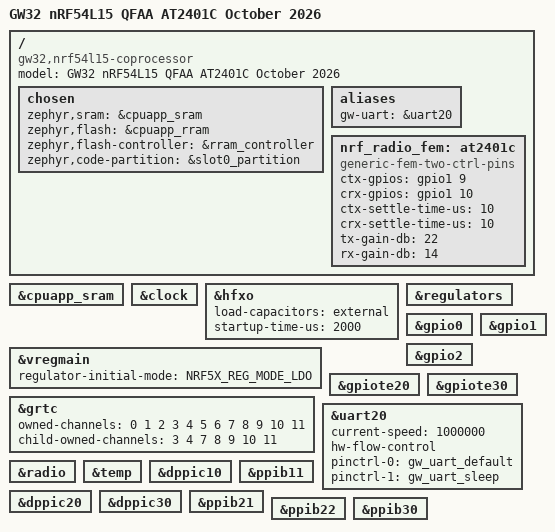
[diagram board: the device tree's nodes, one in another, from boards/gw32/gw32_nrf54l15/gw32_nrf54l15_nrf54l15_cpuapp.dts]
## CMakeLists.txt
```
cmake_minimum_required(VERSION 3.20.0)
list(APPEND BOARD_ROOT ${CMAKE_CURRENT_SOURCE_DIR})
find_package(Zephyr REQUIRED HINTS $ENV{ZEPHYR_BASE})
project(gw32_nrf54l15 VERSION 0.3.0 LANGUAGES C)

target_sources(app PRIVATE
  src/main.c src/gw_app.c src/gw_core.c src/gw_filter_v2.c src/gw_radio.c src/gw_gatt.c
  src/gw_peripheral.c src/gw_dfu.c)
target_include_directories(app PRIVATE src)
target_compile_options(app PRIVATE -Wall -Wextra)
```

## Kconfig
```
mainmenu "GW32 nRF54L15 BLE coprocessor"

config GW_RADIO_VERIFIED
	bool "Enable BLE operation on the selected hardware"
	default y if BOARD_NRF54L15DK
	default n
	help
	  The official DK is usable for software development immediately. For
	  GW32 custom hardware, enable only after validating the schematic
	  revision, oscillator startup and FEM timing and RF output power.
	  With this disabled the UART management protocol remains available
	  and BLE commands report unsupported; no radio capability is advertised.

config GW_DFU
	bool "ESP UART firmware upgrade with signed MCUboot images"
	default n
	depends on BOOTLOADER_MCUBOOT && MCUBOOT_BOOTLOADER_MODE_SWAP_USING_OFFSET
	depends on IMG_MANAGER && IMG_ENABLE_IMAGE_CHECK
	help
	  Receive firmware only into the secondary slot. A trusted, board-specific
	  signing key and a MCUboot sysbuild are required. A normal application
	  build does not advertise UART DFU capability.

config GW_DFU_CONFIRM_TIMEOUT_MS
	int "Trial firmware confirmation timeout (ms)"
	default 120000
	range 30000 600000
	depends on GW_DFU
	help
	  Reset an unconfirmed trial image if ESP does not explicitly confirm it
	  after checking its version and health. MCUboot reverts on the next boot.

source "Kconfig.zephyr"
```

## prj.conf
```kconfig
# UART20 belongs exclusively to the binary gateway protocol.
CONFIG_SERIAL=y
CONFIG_UART_ASYNC_API=y
CONFIG_UART_20_ASYNC=y
CONFIG_UART_USE_RUNTIME_CONFIGURE=y
CONFIG_CONSOLE=n
CONFIG_UART_CONSOLE=n
CONFIG_PRINTK=n

CONFIG_GPIO=y
CONFIG_CLOCK_CONTROL=y
CONFIG_BT=y
CONFIG_BT_CENTRAL=y
CONFIG_BT_OBSERVER=y
CONFIG_BT_BROADCASTER=y
CONFIG_BT_PERIPHERAL=y
CONFIG_BT_GATT_CLIENT=y
CONFIG_BT_MAX_CONN=1
CONFIG_BT_MAX_PAIRED=4
CONFIG_BT_SMP=y
CONFIG_BT_SMP_APP_PAIRING_ACCEPT=y
CONFIG_BT_SETTINGS=y
CONFIG_BT_EXT_ADV=n
CONFIG_BT_DEVICE_NAME="GW32-nRF54L15"
CONFIG_BT_L2CAP_TX_MTU=247
CONFIG_BT_BUF_ACL_RX_SIZE=251
CONFIG_BT_BUF_ACL_TX_SIZE=251

CONFIG_FLASH=y
CONFIG_FLASH_MAP=y
CONFIG_NVS=y
CONFIG_SETTINGS=y
CONFIG_SETTINGS_NVS=y
CONFIG_REBOOT=y
CONFIG_ENTROPY_GENERATOR=y
CONFIG_HARDWARE_DEVICE_CS_GENERATOR=y

# RTT cannot corrupt binary UART frames.
CONFIG_LOG=y
CONFIG_LOG_MODE_DEFERRED=y
CONFIG_LOG_BACKEND_UART=n
CONFIG_USE_SEGGER_RTT=y
CONFIG_LOG_BACKEND_RTT=y
CONFIG_LOG_DEFAULT_LEVEL=3
CONFIG_MAIN_STACK_SIZE=12288
CONFIG_SYSTEM_WORKQUEUE_STACK_SIZE=4096
CONFIG_HEAP_MEM_POOL_SIZE=8192
CONFIG_ASSERT=y
CONFIG_STACK_SENTINEL=y
```

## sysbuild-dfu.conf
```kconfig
SB_CONFIG_BOOTLOADER_MCUBOOT=y
SB_CONFIG_MCUBOOT_MODE_SWAP_USING_OFFSET=y
SB_CONFIG_BOOT_SIGNATURE_TYPE_ECDSA_P256=y
# The build invocation must supply SB_CONFIG_BOOT_SIGNATURE_KEY_FILE.
# Never release an image signed with MCUboot's public example private key.
```

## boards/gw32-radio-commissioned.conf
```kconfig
# Apply only after the commissioning steps in README.md have passed.
CONFIG_GW_RADIO_VERIFIED=y
```

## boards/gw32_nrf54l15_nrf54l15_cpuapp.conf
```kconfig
CONFIG_MPSL_FEM=y
CONFIG_MPSL_FEM_SIMPLE_GPIO=y
CONFIG_GW_RADIO_VERIFIED=n
```

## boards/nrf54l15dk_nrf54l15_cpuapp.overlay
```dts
/* Development kit only. These are protocol pins, not a text console. */
#include <zephyr/dt-bindings/pinctrl/nrf-pinctrl.h>

/ {
	aliases { gw-uart = &uart20; };
};

&pinctrl {
	gw_uart_default: gw_uart_default {
		group1 {
			psels = <NRF_PSEL(UART_TX, 1, 4)>, <NRF_PSEL(UART_RTS, 1, 6)>;
		};
		group2 {
			psels = <NRF_PSEL(UART_RX, 1, 5)>, <NRF_PSEL(UART_CTS, 1, 7)>;
			bias-pull-up;
		};
	};
	gw_uart_sleep: gw_uart_sleep {
		group1 {
			psels = <NRF_PSEL(UART_TX, 1, 4)>, <NRF_PSEL(UART_RX, 1, 5)>,
				<NRF_PSEL(UART_RTS, 1, 6)>, <NRF_PSEL(UART_CTS, 1, 7)>;
			low-power-enable;
		};
	};
};

&uart20 {
	status = "okay";
	current-speed = <1000000>;
	hw-flow-control;
	pinctrl-0 = <&gw_uart_default>;
	pinctrl-1 = <&gw_uart_sleep>;
	pinctrl-names = "default", "sleep";
};
```

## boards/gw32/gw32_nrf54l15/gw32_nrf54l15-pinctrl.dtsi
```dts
#include <zephyr/dt-bindings/pinctrl/nrf-pinctrl.h>

&pinctrl {
	gw_uart_default: gw_uart_default {
		group1 {
			psels = <NRF_PSEL(UART_TX, 1, 4)>, <NRF_PSEL(UART_RTS, 1, 6)>;
		};
		group2 {
			psels = <NRF_PSEL(UART_RX, 1, 5)>, <NRF_PSEL(UART_CTS, 1, 7)>;
			bias-pull-up;
		};
	};
	gw_uart_sleep: gw_uart_sleep {
		group1 {
			psels = <NRF_PSEL(UART_TX, 1, 4)>, <NRF_PSEL(UART_RX, 1, 5)>,
				<NRF_PSEL(UART_RTS, 1, 6)>, <NRF_PSEL(UART_CTS, 1, 7)>;
			low-power-enable;
		};
	};
};
```

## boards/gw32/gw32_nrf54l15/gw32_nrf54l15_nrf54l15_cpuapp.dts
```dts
/dts-v1/;

#include <nordic/nrf54l15_cpuapp.dtsi>
#include <zephyr/dt-bindings/gpio/gpio.h>
#include <zephyr/dt-bindings/regulator/nrf5x.h>
#include "gw32_nrf54l15-pinctrl.dtsi"

/ {
	model = "GW32 nRF54L15 QFAA AT2401C October 2026";
	compatible = "gw32,nrf54l15-coprocessor";
	chosen {
		zephyr,sram = &cpuapp_sram;
		zephyr,flash = &cpuapp_rram;
		zephyr,flash-controller = &rram_controller;
		zephyr,code-partition = &slot0_partition;
	};
	aliases { gw-uart = &uart20; };

	/* NCS v3.2.1 compatible; MPSL owns these pins and their timing. */
	nrf_radio_fem: at2401c {
		compatible = "generic-fem-two-ctrl-pins";
		ctx-gpios = <&gpio1 9 GPIO_ACTIVE_HIGH>;
		crx-gpios = <&gpio1 10 GPIO_ACTIVE_HIGH>;
		/* Datasheet 0.8 us is typical. 10 us is a bench starting value. */
		ctx-settle-time-us = <10>;
		crx-settle-time-us = <10>;
		tx-gain-db = <22>;
		rx-gain-db = <14>;
	};
};

#include <nordic/nrf54l15_partition.dtsi>

&cpuapp_sram { status = "okay"; };
&clock { status = "okay"; };
&hfxo {
	load-capacitors = "external";
	/* Conservative initial allowance, requires XOSTART/XOTUNED measurement. */
	startup-time-us = <2000>;
};
&regulators { status = "okay"; };
&vregmain {
	status = "okay";
	regulator-initial-mode = <NRF5X_REG_MODE_LDO>;
};
&gpio0 { status = "okay"; };
&gpio1 { status = "okay"; };
&gpio2 { status = "okay"; };
&gpiote20 { status = "okay"; };
&gpiote30 { status = "okay"; };
&grtc {
	owned-channels = <0 1 2 3 4 5 6 7 8 9 10 11>;
	child-owned-channels = <3 4 7 8 9 10 11>;
	status = "okay";
};
&uart20 {
	status = "okay";
	current-speed = <1000000>;
	hw-flow-control;
	pinctrl-0 = <&gw_uart_default>;
	pinctrl-1 = <&gw_uart_sleep>;
	pinctrl-names = "default", "sleep";
};
&radio { status = "okay"; };
&temp { status = "okay"; };
&dppic10 { status = "okay"; };
&dppic20 { status = "okay"; };
&dppic30 { status = "okay"; };
&ppib11 { status = "okay"; };
&ppib21 { status = "okay"; };
&ppib22 { status = "okay"; };
&ppib30 { status = "okay"; };
```

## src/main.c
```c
#include <zephyr/kernel.h>
#include <zephyr/logging/log.h>

LOG_MODULE_REGISTER(gw_main, LOG_LEVEL_INF);
int gw_app_run(void);

int main(void)
{
    int err = gw_app_run();
    LOG_ERR("Gateway stopped: %d", err);
    return err;
}
```

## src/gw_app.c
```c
#include "gw_core.h"
#include "gw_gatt.h"
#include "gw_peripheral.h"
#include "gw_dfu.h"
#include "gw_radio.h"
#include <errno.h>
#include <string.h>
#include <zephyr/kernel.h>
#include <zephyr/device.h>
#include <zephyr/drivers/uart.h>
#include <zephyr/drivers/clock_control/nrf_clock_control.h>
#include <zephyr/random/random.h>
#include <zephyr/sys/atomic.h>
#include <zephyr/sys/reboot.h>
#include <zephyr/sys/ring_buffer.h>
#include <zephyr/logging/log.h>

LOG_MODULE_REGISTER(gw_app, LOG_LEVEL_INF);

#define RX_DMA_SIZE 256
#define RX_DMA_COUNT 3
#define RX_RING_SIZE 8192
#define FW_VERSION "gw-nrf54l15/0.3.0"

static const struct device *const link_uart = DEVICE_DT_GET(DT_ALIAS(gw_uart));
static uint8_t rx_dma[RX_DMA_COUNT][RX_DMA_SIZE] __aligned(4);
static atomic_t rx_owned[RX_DMA_COUNT];
static atomic_t rx_disabled = ATOMIC_INIT(1);
static atomic_t rx_overflow;
static atomic_t rx_driver_errors;
static atomic_t tx_busy;
static atomic_t tx_success;
static uint8_t tx_wire[GW_WIRE_MAX] __aligned(4);
RING_BUF_DECLARE(rx_ring, RX_RING_SIZE);
K_SEM_DEFINE(tx_done, 0, 1);
K_MUTEX_DEFINE(queue_lock);

static struct gw_queue queue;
static struct gw_decoder decoder;
static struct gw_frame incoming;
static struct gw_frame outgoing;
static struct gw_frame cached_response;
static uint8_t cached_request[GW_PAYLOAD_MAX];
static uint16_t cached_request_length;
static uint32_t last_command;
static uint8_t boot_id[16];
static uint64_t link_id;
static bool link_established;
static uint64_t dropped_full, bad_rx, retries;
static uint64_t next_batch_send_ms;
static uint64_t ack_deadline_ms;
static uint32_t sent_batch;
static uint32_t retry_backoff_ms = 250;

static int hold_uart_hfxo(void)
{
    /* NCS v3.2.1 UARTE does not own the crystal request. Use the clock
     * manager shared with MPSL; never directly trigger clock hardware. */
    static struct onoff_client client;
    struct onoff_manager *manager =
        z_nrf_clock_control_get_onoff(CLOCK_CONTROL_NRF_SUBSYS_HF);
    if (!manager) {
        return -ENODEV;
    }
    sys_notify_init_spinwait(&client.notify);
    int err = onoff_request(manager, &client);
    if (err < 0) {
        return err;
    }
    int result = 0;
    int64_t deadline = k_uptime_get() + 2000;
    while ((err = sys_notify_fetch_result(&client.notify, &result)) == -EAGAIN &&
           k_uptime_get() < deadline) {
        k_sleep(K_MSEC(1));
    }
    if (err < 0 || result < 0) {
        (void)onoff_cancel_or_release(manager, &client);
        return err < 0 ? err : result;
    }
    /* Continuous RX owns this reference until reboot. */
    return 0;
}

static int claim_rx_buffer(void)
{
    for (int i = 0; i < RX_DMA_COUNT; ++i) {
        if (atomic_cas(&rx_owned[i], 0, 1)) {
            return i;
        }
    }
    return -1;
}

static void uart_event(const struct device *dev, struct uart_event *event, void *unused)
{
    ARG_UNUSED(unused);
    switch (event->type) {
    case UART_RX_RDY: {
        const uint8_t *data = event->data.rx.buf + event->data.rx.offset;
        size_t length = event->data.rx.len;
        if (ring_buf_put(&rx_ring, data, length) != length) {
            atomic_inc(&rx_overflow);
        }
        break;
    }
    case UART_RX_BUF_REQUEST: {
        int slot = claim_rx_buffer();
        if (slot >= 0 && uart_rx_buf_rsp(dev, rx_dma[slot], RX_DMA_SIZE) != 0) {
            atomic_clear(&rx_owned[slot]);
        }
        break;
    }
    case UART_RX_BUF_RELEASED:
        for (int i = 0; i < RX_DMA_COUNT; ++i) {
            if (event->data.rx_buf.buf == rx_dma[i]) {
                atomic_clear(&rx_owned[i]);
                break;
            }
        }
        break;
    case UART_RX_DISABLED:
        atomic_set(&rx_disabled, 1);
        break;
    case UART_RX_STOPPED:
        atomic_inc(&rx_driver_errors);
        break;
    case UART_TX_DONE:
        atomic_set(&tx_success, 1);
        atomic_clear(&tx_busy);
        k_sem_give(&tx_done);
        break;
    case UART_TX_ABORTED:
        atomic_clear(&tx_success);
        atomic_clear(&tx_busy);
        k_sem_give(&tx_done);
        break;
    default:
        break;
    }
}

static void restart_rx(void)
{
    if (!atomic_cas(&rx_disabled, 1, 0)) {
        return;
    }
    int slot = claim_rx_buffer();
    if (slot < 0) {
        atomic_set(&rx_disabled, 1);
        return;
    }
    /* A short idle timeout delivers a partial command without awaiting 256 bytes. */
    int err = uart_rx_enable(link_uart, rx_dma[slot], RX_DMA_SIZE, 1000);
    if (err) {
        atomic_clear(&rx_owned[slot]);
        atomic_set(&rx_disabled, 1);
    }
}

static int send_frame(const struct gw_frame *frame)
{
    if (atomic_get(&tx_busy)) {
        return -EBUSY;
    }
    size_t length = gw_encode_frame(frame, tx_wire, sizeof(tx_wire));
    if (!length) {
        return -EINVAL;
    }
    k_sem_reset(&tx_done);
    atomic_clear(&tx_success);
    atomic_set(&tx_busy, 1);
    /* The DMA buffer is never reused until DONE or ABORTED releases ownership. */
    int err = uart_tx(link_uart, tx_wire, length, 200000);
    if (err) {
        atomic_clear(&tx_busy);
        return err;
    }
    if (k_sem_take(&tx_done, K_MSEC(300))) {
        (void)uart_tx_abort(link_uart);
        (void)k_sem_take(&tx_done, K_MSEC(100));
        return -ETIMEDOUT;
    }
    return atomic_get(&tx_success) ? 0 : -ETIMEDOUT;
}

bool gw_app_record(uint8_t type, const uint8_t *record, size_t length)
{
    k_mutex_lock(&queue_lock, K_FOREVER);
    bool accepted = gw_queue_push(&queue, type, record, length, k_uptime_get());
    if (!accepted) {
        dropped_full++;
    }
    k_mutex_unlock(&queue_lock);
    return accepted;
}

static void gatt_record(const uint8_t *record, size_t length)
{
    (void)gw_app_record(0x21, record, length);
}

static size_t encode_status(uint8_t *out)
{
    uint64_t seen, filtered, incomplete;
    gw_radio_counters(&seen, &filtered, &incomplete);
    gw_put_u64(out, k_uptime_get());
    gw_put_u64(out + 8, gw_radio_revision());
    out[16] = gw_radio_scan_state();
    k_mutex_lock(&queue_lock, K_FOREVER);
    gw_put_u16(out + 17, queue.count);
    gw_put_u32(out + 19, queue.used_bytes);
    gw_put_u64(out + 39, dropped_full);
    k_mutex_unlock(&queue_lock);
    gw_put_u64(out + 23, seen);
    gw_put_u64(out + 31, filtered);
    gw_put_u64(out + 47, incomplete);
    gw_put_u64(out + 55, bad_rx);
    gw_put_u64(out + 63, retries);
    return 71;
}

static uint8_t dispatch_command(uint8_t opcode, const uint8_t *args, size_t length,
                                uint8_t *out, size_t *out_length, uint64_t received_ms)
{
    *out_length = 0;
    if (opcode >= 0x30 && opcode <= 0x37) {
        return gw_dfu_command(opcode, args, length, out, out_length);
    }
    if (gw_dfu_active() && opcode != 0x02 && opcode != 0x03 && opcode != 0x04 &&
        opcode != 0x06 && opcode != 0x08 && opcode != 0x09 && opcode != 0x0a &&
        opcode != 0x0c && opcode != 0x0d && opcode != 0x17 &&
        opcode != 0x1a && opcode != 0x1b) {
        return GW_BUSY;
    }
    switch (opcode) {
    case 0x03:
        if (length) {
            return GW_BAD_PARAM;
        }
        *out_length = encode_status(out);
        return GW_OK;
    case 0x04:
        if (length) {
            return GW_BAD_PARAM;
        }
        gw_put_u64(out, received_ms);
        gw_put_u64(out + 8, k_uptime_get());
        *out_length = 16;
        return GW_OK;
    case 0x0a:
    case 0x10: case 0x11: case 0x12: case 0x13: case 0x14:
    case 0x15: case 0x16: case 0x17: case 0x18:
        if (!(gw_radio_capabilities() & BIT(2))) {
            return GW_UNSUPPORTED;
        }
        return gw_gatt_command(opcode, args, length, out, out_length);
    case 0x0d: case 0x0e: case 0x0f:
        if (!(gw_radio_capabilities() & BIT(11))) {
            return GW_UNSUPPORTED;
        }
        return gw_peripheral_command(opcode, args, length, out, out_length);
    default:
        return gw_radio_command(opcode, args, length, out, out_length);
    }
}

static void handle_hello(const struct gw_frame *request)
{
    if (request->payload_len || request->msg_id || !request->link_id) {
        bad_rx++;
        return;
    }
    if (request->link_id != link_id) {
        link_id = request->link_id;
        last_command = 0;
        cached_request_length = 0;
        /* FIFO, frozen batch, config, conn_id and GATT op cache survive relinking. */
    }
    link_established = false;
    outgoing.type = 0x81;
    outgoing.link_id = link_id;
    outgoing.msg_id = 0;
    memcpy(outgoing.payload, boot_id, sizeof(boot_id));
    gw_put_u32(outgoing.payload + 16, gw_radio_capabilities() |
               (gw_dfu_available() ? BIT(12) : 0));
    outgoing.payload[20] = sizeof(FW_VERSION) - 1;
    memcpy(outgoing.payload + 21, FW_VERSION, sizeof(FW_VERSION) - 1);
    outgoing.payload_len = 21 + sizeof(FW_VERSION) - 1;
    if (send_frame(&outgoing) == 0) {
        link_established = true;
        ack_deadline_ms = 0;
        next_batch_send_ms = k_uptime_get();
    }
}

static void handle_command(const struct gw_frame *request, uint64_t received_ms)
{
    if (!request->msg_id || !request->payload_len) {
        bad_rx++;
        return;
    }
    if (request->msg_id < last_command) {
        return;
    }
    if (request->msg_id == last_command) {
        if (request->payload_len == cached_request_length &&
            !memcmp(request->payload, cached_request, cached_request_length)) {
            (void)send_frame(&cached_response);
        } else {
            outgoing.type = 0x90;
            outgoing.link_id = link_id;
            outgoing.msg_id = request->msg_id;
            outgoing.payload_len = 2;
            outgoing.payload[0] = request->payload[0];
            outgoing.payload[1] = GW_CONFLICT;
            (void)send_frame(&outgoing);
        }
        return;
    }
    uint8_t opcode = request->payload[0];
    cached_response.type = 0x90;
    cached_response.link_id = link_id;
    cached_response.msg_id = request->msg_id;
    cached_response.payload[0] = opcode;
    size_t result_length = 0;
    uint8_t status = dispatch_command(opcode, request->payload + 1,
                                     request->payload_len - 1,
                                     cached_response.payload + 2, &result_length,
                                     received_ms);
    cached_response.payload[1] = status;
    cached_response.payload_len = 2 + (status == GW_OK ? result_length : 0);
    last_command = request->msg_id;
    cached_request_length = request->payload_len;
    memcpy(cached_request, request->payload, cached_request_length);
    /* Cache even when TX fails: a host retry must not repeat a physical action. */
    (void)send_frame(&cached_response);
}

static void handle_ack(const struct gw_frame *request)
{
    if (request->payload_len != 3) {
        bad_rx++;
        return;
    }
    uint8_t status = request->payload[0];
    uint16_t interval = gw_get_u16(request->payload + 1);
    if (status > 2 || (status == 1 ? (interval < 250 || interval > 5000) : interval != 0)) {
        bad_rx++;
        return;
    }
    k_mutex_lock(&queue_lock, K_FOREVER);
    bool matched = gw_queue_ack(&queue, request->msg_id, status);
    k_mutex_unlock(&queue_lock);
    if (!matched) {
        return;
    }
    ack_deadline_ms = 0;
    next_batch_send_ms = k_uptime_get() + interval;
    if (status == 0) {
        sent_batch = 0;
        retry_backoff_ms = 250;
    }
}

static void receive_frames(void)
{
    uint8_t bytes[128];
    uint32_t count;
    uint32_t overflow = atomic_set(&rx_overflow, 0);
    uint32_t driver_errors = atomic_set(&rx_driver_errors, 0);
    if (overflow || driver_errors) {
        bad_rx += overflow + driver_errors;
        decoder.length = 0;
        decoder.discard = true;
    }
    /* Bound each turn so notifications, deadlines and driver recovery progress. */
    for (size_t budget = 0; budget < RX_RING_SIZE; budget += count) {
        count = ring_buf_get(&rx_ring, bytes, sizeof(bytes));
        if (!count) {
            break;
        }
        for (size_t i = 0; i < count; ++i) {
            int decoded = gw_decoder_feed(&decoder, bytes[i], &incoming);
            if (decoded < 0) {
                bad_rx++;
            } else if (decoded > 0) {
                uint64_t received_ms = k_uptime_get();
                if (incoming.type == 0x01) {
                    handle_hello(&incoming);
                } else if (link_established && incoming.link_id == link_id) {
                    if (incoming.type == 0x10) {
                        handle_command(&incoming, received_ms);
                    } else if (incoming.type == 0xa0) {
                        handle_ack(&incoming);
                    } else {
                        bad_rx++;
                    }
                }
            }
        }
    }
}

static void transmit_batch(void)
{
    uint64_t now = k_uptime_get();
    if (!link_established || atomic_get(&tx_busy)) {
        return;
    }
    if (ack_deadline_ms) {
        if (now < ack_deadline_ms) {
            return;
        }
        ack_deadline_ms = 0;
        next_batch_send_ms = now + retry_backoff_ms + sys_rand32_get() % 101;
        retry_backoff_ms = MIN(retry_backoff_ms * 2, 5000);
    }
    if (now < next_batch_send_ms) {
        return;
    }
    k_mutex_lock(&queue_lock, K_FOREVER);
    bool ready = gw_queue_batch(&queue, now, &outgoing);
    bool exhausted = !queue.count && (queue.next_sequence == UINT64_MAX || !queue.next_batch);
    k_mutex_unlock(&queue_lock);
    if (exhausted) {
        sys_reboot(SYS_REBOOT_COLD);
        return;
    }
    if (!ready) {
        return;
    }
    outgoing.link_id = link_id;
    if (sent_batch == outgoing.msg_id) {
        retries++;
    }
    sent_batch = outgoing.msg_id;
    if (send_frame(&outgoing) == 0) {
        ack_deadline_ms = k_uptime_get() + 500;
    } else {
        next_batch_send_ms = k_uptime_get() + retry_backoff_ms + sys_rand32_get() % 101;
        retry_backoff_ms = MIN(retry_backoff_ms * 2, 5000);
    }
}

int gw_app_run(void)
{
    gw_queue_init(&queue);
    gw_decoder_init(&decoder);
    int err = gw_dfu_init();
    if (err) {
        LOG_ERR("DFU unavailable (%d); UART diagnostics remain enabled", err);
    }
    /* Never reuse a constant boot identifier if the entropy device fails. */
    err = hold_uart_hfxo();
    if (err) {
        return err;
    }
    err = sys_csrand_get(boot_id, sizeof(boot_id));
    if (err) {
        return err;
    }
    err = gw_radio_init();
    if (err) {
        LOG_ERR("Bluetooth unavailable (%d); UART diagnostics remain enabled", err);
    }
    err = gw_gatt_init(gatt_record);
    if (err) {
        return err;
    }
    err = gw_peripheral_init();
    if (err) {
        return err;
    }
    if (!device_is_ready(link_uart)) {
        return -ENODEV;
    }
    const struct uart_config config = {
        .baudrate = 1000000,
        .parity = UART_CFG_PARITY_NONE,
        .stop_bits = UART_CFG_STOP_BITS_1,
        .data_bits = UART_CFG_DATA_BITS_8,
        .flow_ctrl = UART_CFG_FLOW_CTRL_RTS_CTS,
    };
    err = uart_configure(link_uart, &config);
    if (err) {
        return err;
    }
    err = uart_callback_set(link_uart, uart_event, NULL);
    if (err) {
        return err;
    }
    LOG_INF("Gateway %s started (capabilities 0x%x)", FW_VERSION, gw_radio_capabilities());
    restart_rx();
    for (;;) {
        restart_rx();
        receive_frames();
        gw_gatt_poll();
        gw_peripheral_poll();
        gw_dfu_poll();
        gw_radio_poll();
        transmit_batch();
        k_sleep(K_MSEC(1));
    }
}
```

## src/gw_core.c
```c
#include "gw_core.h"

#include <limits.h>
#include <string.h>

uint16_t gw_get_u16(const uint8_t *p)
{
    return (uint16_t)p[0] | (uint16_t)((uint16_t)p[1] << 8);
}

uint32_t gw_get_u32(const uint8_t *p)
{
    return (uint32_t)p[0] | ((uint32_t)p[1] << 8) |
           ((uint32_t)p[2] << 16) | ((uint32_t)p[3] << 24);
}

uint64_t gw_get_u64(const uint8_t *p)
{
    return (uint64_t)gw_get_u32(p) | ((uint64_t)gw_get_u32(p + 4) << 32);
}

void gw_put_u16(uint8_t *p, uint16_t value)
{
    p[0] = (uint8_t)value;
    p[1] = (uint8_t)(value >> 8);
}

void gw_put_u32(uint8_t *p, uint32_t value)
{
    for (unsigned int i = 0; i < 4; ++i) {
        p[i] = (uint8_t)(value >> (i * 8));
    }
}

void gw_put_u64(uint8_t *p, uint64_t value)
{
    gw_put_u32(p, (uint32_t)value);
    gw_put_u32(p + 4, (uint32_t)(value >> 32));
}

uint32_t gw_crc32c(const uint8_t *data, size_t length)
{
    uint32_t crc = UINT32_MAX;

    for (size_t i = 0; i < length; ++i) {
        crc ^= data[i];
        for (unsigned int bit = 0; bit < 8; ++bit) {
            uint32_t mask = 0U - (crc & 1U);
            crc = (crc >> 1) ^ (UINT32_C(0x82f63b78) & mask);
        }
    }
    return crc ^ UINT32_MAX;
}

size_t gw_encode_frame(const struct gw_frame *frame, uint8_t *wire, size_t capacity)
{
    uint8_t raw[GW_RAW_MAX];
    size_t raw_length;
    size_t written = 2;
    size_t code_offset = 1;
    uint8_t code = 1;

    if (frame == NULL || wire == NULL || frame->payload_len > GW_PAYLOAD_MAX) {
        return 0;
    }
    raw_length = 22U + frame->payload_len;
    if (capacity < raw_length + raw_length / 254U + 3U) {
        return 0;
    }
    raw[0] = 0x47;
    raw[1] = 0x57;
    raw[2] = 1;
    raw[3] = frame->type;
    gw_put_u16(raw + 4, frame->payload_len);
    gw_put_u64(raw + 6, frame->link_id);
    gw_put_u32(raw + 14, frame->msg_id);
    memcpy(raw + 18, frame->payload, frame->payload_len);
    gw_put_u32(raw + raw_length - 4, gw_crc32c(raw, raw_length - 4));
    wire[0] = 0;
    for (size_t i = 0; i < raw_length; ++i) {
        if (raw[i] == 0) {
            wire[code_offset] = code;
            code_offset = written++;
            code = 1;
        } else {
            wire[written++] = raw[i];
            ++code;
            if (code == 255) {
                wire[code_offset] = code;
                code_offset = written++;
                code = 1;
            }
        }
    }
    wire[code_offset] = code;
    wire[written++] = 0;
    return written;
}

bool gw_decode_frame(const uint8_t *encoded, size_t length, struct gw_frame *frame)
{
    uint8_t raw[GW_RAW_MAX];
    size_t pos = 0;
    size_t decoded = 0;

    if (encoded == NULL || frame == NULL || length == 0 || length > GW_ENCODED_MAX) {
        return false;
    }
    while (pos < length) {
        uint8_t code = encoded[pos++];
        size_t run = (size_t)code - 1U;

        if (code == 0 || run > length - pos || run > sizeof(raw) - decoded) {
            return false;
        }
        for (size_t i = 0; i < run; ++i) {
            if (encoded[pos + i] == 0) {
                return false;
            }
        }
        memcpy(raw + decoded, encoded + pos, run);
        decoded += run;
        pos += run;
        if (code < 255 && pos < length) {
            if (decoded == sizeof(raw)) {
                return false;
            }
            raw[decoded++] = 0;
        }
    }
    if (decoded < 22 || raw[0] != 0x47 || raw[1] != 0x57 || raw[2] != 1 ||
        gw_get_u16(raw + 4) != decoded - 22 ||
        gw_get_u32(raw + decoded - 4) != gw_crc32c(raw, decoded - 4)) {
        return false;
    }
    frame->type = raw[3];
    frame->payload_len = gw_get_u16(raw + 4);
    frame->link_id = gw_get_u64(raw + 6);
    frame->msg_id = gw_get_u32(raw + 14);
    memcpy(frame->payload, raw + 18, frame->payload_len);
    return true;
}

void gw_decoder_init(struct gw_decoder *decoder)
{
    memset(decoder, 0, sizeof(*decoder));
}

int gw_decoder_feed(struct gw_decoder *decoder, uint8_t byte, struct gw_frame *frame)
{
    if (byte == 0) {
        int result = 0;

        if (decoder->discard) {
            result = -1;
        } else if (decoder->length != 0) {
            result = gw_decode_frame(decoder->encoded, decoder->length, frame) ? 1 : -1;
        }
        decoder->length = 0;
        decoder->discard = false;
        return result;
    }
    if (!decoder->discard) {
        if (decoder->length == sizeof(decoder->encoded)) {
            decoder->discard = true;
        } else {
            decoder->encoded[decoder->length++] = byte;
        }
    }
    return 0;
}

void gw_profile_default(struct gw_profile *profile)
{
    memset(profile, 0, sizeof(*profile));
    profile->interval_ticks = 160;
    profile->window_ticks = 80;
    profile->min_rssi = INT8_MIN;
}

static bool parse_scan(const uint8_t *data, size_t length, struct gw_profile *profile)
{
    size_t pos;

    if (length < 16) {
        return false;
    }
    profile->revision = gw_get_u64(data);
    profile->scan_flags = data[8];
    profile->interval_ticks = gw_get_u16(data + 9);
    profile->window_ticks = gw_get_u16(data + 11);
    profile->min_rssi = (int8_t)data[13];
    profile->uuid_count = data[14];
    if ((profile->scan_flags & ~3U) != 0 || profile->interval_ticks < 16 ||
        profile->interval_ticks > 16384 || profile->window_ticks < 16 ||
        profile->window_ticks > profile->interval_ticks || profile->min_rssi > 20 ||
        profile->uuid_count > GW_UUIDS_MAX) {
        return false;
    }
    pos = 15U + (size_t)profile->uuid_count * 16U;
    if (pos >= length) {
        return false;
    }
    memcpy(profile->uuids, data + 15, (size_t)profile->uuid_count * 16U);
    for (unsigned int i = 1; i < profile->uuid_count; ++i) {
        if (memcmp(profile->uuids[i - 1], profile->uuids[i], 16) >= 0) {
            return false;
        }
    }
    profile->company_count = data[pos++];
    if (profile->company_count > GW_UUIDS_MAX ||
        length - pos != (size_t)profile->company_count * 2U) {
        return false;
    }
    for (unsigned int i = 0; i < profile->company_count; ++i) {
        profile->companies[i] = gw_get_u16(data + pos);
        pos += 2;
        if (i != 0 && profile->companies[i - 1] >= profile->companies[i]) {
            return false;
        }
    }
    return true;
}

bool gw_profile_parse(const uint8_t *data, size_t length, bool extended,
                      struct gw_profile *profile)
{
    struct gw_profile candidate = {0};
    size_t pos = 0;
    size_t scan_length = length;

    if (data == NULL || profile == NULL || length > GW_PROFILE_MAX) {
        return false;
    }
    if (extended) {
        if (length < 19) {
            return false;
        }
        scan_length = gw_get_u16(data);
        pos = 2;
        if (scan_length > length - 3) {
            return false;
        }
    }
    if (!parse_scan(data + pos, scan_length, &candidate)) {
        return false;
    }
    pos += scan_length;
    if (extended) {
        candidate.rule_count = data[pos++];
        if (candidate.rule_count > GW_RULES_MAX) {
            return false;
        }
        for (unsigned int i = 0; i < candidate.rule_count; ++i) {
            struct gw_beacon_rule *rule = &candidate.rules[i];
            uint8_t mask_bits = 0;

            if (length - pos < 6) {
                return false;
            }
            rule->action = data[pos++];
            rule->kind_mask = data[pos++];
            rule->ad_type = data[pos++];
            rule->offset = gw_get_u16(data + pos);
            pos += 2;
            rule->length = data[pos++];
            if (rule->action > 1 || rule->kind_mask == 0 || rule->kind_mask > 15 ||
                rule->ad_type == 0 || rule->length == 0 || rule->length > 24 ||
                (uint32_t)rule->offset + rule->length > 254 ||
                length - pos < (size_t)rule->length * 2U) {
                return false;
            }
            memcpy(rule->value, data + pos, rule->length);
            pos += rule->length;
            memcpy(rule->mask, data + pos, rule->length);
            pos += rule->length;
            for (unsigned int j = 0; j < rule->length; ++j) {
                mask_bits |= rule->mask[j];
            }
            if (mask_bits == 0) {
                return false;
            }
        }
    }
    if (pos != length) {
        return false;
    }
    *profile = candidate;
    return true;
}

size_t gw_profile_encode(const struct gw_profile *profile, bool extended,
                         uint8_t *data, size_t capacity)
{
    size_t scan_length;
    size_t needed;
    size_t pos = 0;

    if (profile == NULL || data == NULL || profile->uuid_count > GW_UUIDS_MAX ||
        profile->company_count > GW_UUIDS_MAX || profile->rule_count > GW_RULES_MAX) {
        return 0;
    }
    scan_length = 16U + (size_t)profile->uuid_count * 16U +
                  (size_t)profile->company_count * 2U;
    needed = scan_length;
    if (extended) {
        needed += 3;
        for (unsigned int i = 0; i < profile->rule_count; ++i) {
            if (profile->rules[i].length == 0 || profile->rules[i].length > 24) {
                return 0;
            }
            needed += 6U + (size_t)profile->rules[i].length * 2U;
        }
    }
    if (capacity < needed) {
        return 0;
    }
    if (extended) {
        gw_put_u16(data, (uint16_t)scan_length);
        pos = 2;
    }
    gw_put_u64(data + pos, profile->revision);
    data[pos + 8] = profile->scan_flags;
    gw_put_u16(data + pos + 9, profile->interval_ticks);
    gw_put_u16(data + pos + 11, profile->window_ticks);
    data[pos + 13] = (uint8_t)profile->min_rssi;
    data[pos + 14] = profile->uuid_count;
    pos += 15;
    memcpy(data + pos, profile->uuids, (size_t)profile->uuid_count * 16U);
    pos += (size_t)profile->uuid_count * 16U;
    data[pos++] = profile->company_count;
    for (unsigned int i = 0; i < profile->company_count; ++i) {
        gw_put_u16(data + pos, profile->companies[i]);
        pos += 2;
    }
    if (extended) {
        data[pos++] = profile->rule_count;
        for (unsigned int i = 0; i < profile->rule_count; ++i) {
            const struct gw_beacon_rule *rule = &profile->rules[i];

            data[pos++] = rule->action;
            data[pos++] = rule->kind_mask;
            data[pos++] = rule->ad_type;
            gw_put_u16(data + pos, rule->offset);
            pos += 2;
            data[pos++] = rule->length;
            memcpy(data + pos, rule->value, rule->length);
            pos += rule->length;
            memcpy(data + pos, rule->mask, rule->length);
            pos += rule->length;
        }
    }
    return pos;
}

bool gw_ad_valid(const uint8_t *ad, size_t length)
{
    size_t pos = 0;

    if (ad == NULL && length != 0) {
        return false;
    }
    while (pos < length) {
        uint8_t field_length = ad[pos++];

        if (field_length == 0) {
            while (pos < length) {
                if (ad[pos++] != 0) {
                    return false;
                }
            }
            return true;
        }
        if (field_length > length - pos) {
            return false;
        }
        pos += field_length;
    }
    return true;
}

static void normalize_uuid(const uint8_t *wire, size_t width, uint8_t uuid[16])
{
    static const uint8_t base[16] = {
        0, 0, 0, 0, 0, 0, 0x10, 0, 0x80, 0, 0, 0x80, 0x5f, 0x9b, 0x34, 0xfb
    };
    size_t offset = width == 16 ? 0 : 4U - width;

    memcpy(uuid, base, 16);
    for (size_t i = 0; i < width; ++i) {
        uuid[offset + i] = wire[width - 1U - i];
    }
}

static bool uuid_field_matches(const struct gw_profile *profile, uint8_t type,
                               const uint8_t *data, size_t length)
{
    size_t width;
    bool service_data;

    switch (type) {
    case 0x02: case 0x03: case 0x16: width = 2; break;
    case 0x04: case 0x05: case 0x20: width = 4; break;
    case 0x06: case 0x07: case 0x21: width = 16; break;
    default: return false;
    }
    service_data = type == 0x16 || type == 0x20 || type == 0x21;
    if (length < width || (!service_data && length % width != 0)) {
        return false;
    }
    if (service_data) {
        length = width;
    }
    for (size_t pos = 0; pos < length; pos += width) {
        uint8_t uuid[16];

        normalize_uuid(data + pos, width, uuid);
        for (unsigned int i = 0; i < profile->uuid_count; ++i) {
            if (memcmp(profile->uuids[i], uuid, 16) == 0) {
                return true;
            }
        }
    }
    return false;
}

static bool rule_matches(const struct gw_beacon_rule *rule, uint8_t kind,
                         uint8_t type, const uint8_t *data, size_t length)
{
    if ((rule->kind_mask & (1U << kind)) == 0 || rule->ad_type != type ||
        (size_t)rule->offset + rule->length > length) {
        return false;
    }
    for (unsigned int i = 0; i < rule->length; ++i) {
        if ((data[rule->offset + i] & rule->mask[i]) != (rule->value[i] & rule->mask[i])) {
            return false;
        }
    }
    return true;
}

bool gw_filter_match(const struct gw_profile *profile, uint8_t kind, int8_t rssi,
                     const uint8_t *ad, size_t length)
{
    bool uuid_match;
    bool company_match;
    bool matched_rules[GW_RULES_MAX] = {false};
    bool has_allow = false;
    size_t pos = 0;

    if (profile == NULL || kind > 3 || (profile->scan_flags & 1U) == 0 ||
        (ad == NULL && length != 0)) {
        return false;
    }
    if (profile->min_rssi != INT8_MIN &&
        (rssi == INT8_MIN || rssi < profile->min_rssi)) {
        return false;
    }
    /* With no content filters, retain malformed AD for server diagnostics. */
    if (profile->uuid_count == 0 && profile->company_count == 0 && profile->rule_count == 0) {
        return true;
    }
    uuid_match = profile->uuid_count == 0;
    company_match = profile->company_count == 0;
    while (pos < length && ad[pos] != 0) {
        uint8_t field_length = ad[pos];
        uint8_t type;
        const uint8_t *data;
        size_t data_length;

        /* A malformed tail cannot be matched or joined to a previous field. */
        if (field_length > length - pos - 1U) {
            break;
        }
        type = ad[pos + 1];
        data = ad + pos + 2;
        data_length = (size_t)field_length - 1U;

        if (!uuid_match) {
            uuid_match = uuid_field_matches(profile, type, data, data_length);
        }
        if (!company_match && type == 0xff && data_length >= 2) {
            uint16_t company = gw_get_u16(data);

            for (unsigned int i = 0; i < profile->company_count; ++i) {
                company_match |= profile->companies[i] == company;
            }
        }
        for (unsigned int i = 0; i < profile->rule_count; ++i) {
            matched_rules[i] |= rule_matches(&profile->rules[i], kind, type, data, data_length);
        }
        pos += (size_t)field_length + 1U;
    }
    if (!uuid_match || !company_match) {
        return false;
    }
    for (unsigned int i = 0; i < profile->rule_count; ++i) {
        if (matched_rules[i]) {
            return profile->rules[i].action == 1;
        }
        has_allow |= profile->rules[i].action == 1;
    }
    return !has_allow;
}

void gw_queue_init(struct gw_queue *queue)
{
    memset(queue, 0, sizeof(*queue));
    queue->next_sequence = 1;
    queue->next_batch = 1;
}

static bool record_valid(uint8_t type, const uint8_t *record, size_t length)
{
    if (record == NULL || length < 24 || length > GW_BATCH_MAX - 10 ||
        gw_get_u16(record + 22) != length - 24) {
        return false;
    }
    if (type == 0x20) {
        return record[8] < 4 && length - 24 <= (record[8] < 2 ? 31U : 1650U);
    }
    if (type == 0x21) {
        return record[21] <= 1 && length - 24 <= 512;
    }
    if (type == 0x22) {
        return record[21] == 0 && gw_get_u16(record + 19) == 1 &&
               length > 24 && length - 24 <= 512;
    }
    return false;
}

bool gw_queue_push(struct gw_queue *queue, uint8_t type, const uint8_t *record,
                   size_t length, uint64_t now_ms)
{
    struct gw_queued_record *item;
    size_t first_length;

    if (!record_valid(type, record, length) || queue->count == GW_QUEUE_RECORDS ||
        length > GW_QUEUE_BYTES - queue->used_bytes ||
        queue->next_sequence == UINT64_MAX || queue->next_batch == 0 ||
        queue->next_batch > UINT32_MAX - queue->count) {
        return false;
    }
    item = &queue->records[(queue->head + queue->count) % GW_QUEUE_RECORDS];
    item->offset = queue->write_offset;
    item->length = (uint16_t)length;
    item->type = type;
    item->sequence = queue->next_sequence++;
    item->queued_ms = now_ms;
    first_length = GW_QUEUE_BYTES - queue->write_offset;
    if (first_length > length) {
        first_length = length;
    }
    memcpy(queue->bytes + queue->write_offset, record, first_length);
    memcpy(queue->bytes, record + first_length, length - first_length);
    queue->write_offset = (uint16_t)((queue->write_offset + length) % GW_QUEUE_BYTES);
    queue->used_bytes += (uint32_t)length;
    ++queue->count;
    return true;
}

static void copy_record(const struct gw_queue *queue, const struct gw_queued_record *record,
                        uint8_t *destination)
{
    size_t first_length = GW_QUEUE_BYTES - record->offset;

    if (first_length > record->length) {
        first_length = record->length;
    }
    memcpy(destination, queue->bytes + record->offset, first_length);
    memcpy(destination + first_length, queue->bytes, record->length - first_length);
}

bool gw_queue_batch(struct gw_queue *queue, uint64_t now_ms, struct gw_frame *frame)
{
    const struct gw_queued_record *first;
    uint16_t count = 0;
    size_t length = 10;

    if (queue->fault || queue->count == 0 || queue->next_batch == 0) {
        return false;
    }
    first = &queue->records[queue->head];
    if (queue->inflight_count != 0) {
        count = queue->inflight_count;
    } else {
        while (count < queue->count && count < 32) {
            const struct gw_queued_record *item =
                &queue->records[(queue->head + count) % GW_QUEUE_RECORDS];

            if (item->type != first->type || item->length > GW_BATCH_MAX - length) {
                break;
            }
            length += item->length;
            ++count;
        }
        if (count == queue->count && count < 32 &&
            (now_ms < first->queued_ms || now_ms - first->queued_ms < 50)) {
            return false;
        }
        queue->inflight_count = count;
        queue->inflight_batch = queue->next_batch;
    }
    frame->type = first->type;
    frame->msg_id = queue->inflight_batch;
    gw_put_u16(frame->payload, count);
    gw_put_u64(frame->payload + 2, first->sequence);
    length = 10;
    for (uint16_t i = 0; i < count; ++i) {
        const struct gw_queued_record *item =
            &queue->records[(queue->head + i) % GW_QUEUE_RECORDS];

        copy_record(queue, item, frame->payload + length);
        length += item->length;
    }
    frame->payload_len = (uint16_t)length;
    return true;
}

bool gw_queue_ack(struct gw_queue *queue, uint32_t batch, uint8_t status)
{
    if (queue->fault || queue->inflight_count == 0 ||
        batch != queue->inflight_batch || status > 2) {
        return false;
    }
    if (status == 2) {
        queue->fault = true;
    } else if (status == 0) {
        for (uint16_t i = 0; i < queue->inflight_count; ++i) {
            queue->used_bytes -= queue->records[queue->head].length;
            queue->head = (uint16_t)((queue->head + 1U) % GW_QUEUE_RECORDS);
        }
        queue->count -= queue->inflight_count;
        queue->inflight_count = 0;
        queue->inflight_batch = 0;
        ++queue->next_batch;
    }
    return true;
}
```

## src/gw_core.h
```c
#ifndef GW_CORE_H
#define GW_CORE_H

#include <stdbool.h>
#include <stddef.h>
#include <stdint.h>

#define GW_PAYLOAD_MAX 3072U
#define GW_RAW_MAX 3094U
#define GW_ENCODED_MAX 3107U
#define GW_WIRE_MAX 3109U
#define GW_BATCH_MAX 2048U
#define GW_QUEUE_RECORDS 128U
#define GW_QUEUE_BYTES 32768U
#define GW_UUIDS_MAX 128U
#define GW_RULES_MAX 8U
#define GW_PROFILE_MAX 2755U

enum gw_status {
    GW_OK = 0, GW_BAD_PARAM = 1, GW_UNSUPPORTED = 2, GW_BUSY = 3,
    GW_CONFLICT = 4, GW_APPLY_FAILED = 5, GW_STALE = 6, GW_NOT_FOUND = 7
};

struct gw_frame {
    uint8_t type;
    uint64_t link_id;
    uint32_t msg_id;
    uint16_t payload_len;
    uint8_t payload[GW_PAYLOAD_MAX];
};

struct gw_decoder {
    uint8_t encoded[GW_ENCODED_MAX];
    size_t length;
    bool discard;
};

uint16_t gw_get_u16(const uint8_t *p);
uint32_t gw_get_u32(const uint8_t *p);
uint64_t gw_get_u64(const uint8_t *p);
void gw_put_u16(uint8_t *p, uint16_t value);
void gw_put_u32(uint8_t *p, uint32_t value);
void gw_put_u64(uint8_t *p, uint64_t value);
uint32_t gw_crc32c(const uint8_t *data, size_t length);
/* Returns encoded length including both delimiters, or zero on invalid input. */
size_t gw_encode_frame(const struct gw_frame *frame, uint8_t *wire, size_t capacity);
/* Decode one COBS segment, without the zero delimiters. */
bool gw_decode_frame(const uint8_t *encoded, size_t length, struct gw_frame *frame);
void gw_decoder_init(struct gw_decoder *decoder);
/* 1 = complete frame, 0 = incomplete/empty, -1 = one invalid segment. */
int gw_decoder_feed(struct gw_decoder *decoder, uint8_t byte, struct gw_frame *frame);

struct gw_beacon_rule {
    uint8_t action;
    uint8_t kind_mask;
    uint8_t ad_type;
    uint16_t offset;
    uint8_t length;
    uint8_t value[24];
    uint8_t mask[24];
};

struct gw_profile {
    uint64_t revision;
    uint8_t scan_flags;
    uint16_t interval_ticks;
    uint16_t window_ticks;
    int8_t min_rssi;
    uint8_t uuid_count;
    uint8_t uuids[GW_UUIDS_MAX][16];
    uint8_t company_count;
    uint16_t companies[GW_UUIDS_MAX];
    uint8_t rule_count;
    struct gw_beacon_rule rules[GW_RULES_MAX];
};

void gw_profile_default(struct gw_profile *profile);
/* extended=false parses ScanConfig, true parses ScanProfile. Output changes only on success. */
bool gw_profile_parse(const uint8_t *data, size_t length, bool extended,
                      struct gw_profile *profile);
size_t gw_profile_encode(const struct gw_profile *profile, bool extended,
                         uint8_t *data, size_t capacity);
bool gw_ad_valid(const uint8_t *ad, size_t length);
/* Complete input report, kind 0..3. A disabled profile never matches. */
bool gw_filter_match(const struct gw_profile *profile, uint8_t kind, int8_t rssi,
                     const uint8_t *ad, size_t length);

struct gw_queued_record {
    uint16_t offset;
    uint16_t length;
    uint8_t type;
    uint64_t sequence;
    uint64_t queued_ms;
};

struct gw_queue {
    uint8_t bytes[GW_QUEUE_BYTES];
    struct gw_queued_record records[GW_QUEUE_RECORDS];
    uint16_t head;
    uint16_t count;
    uint16_t write_offset;
    uint32_t used_bytes;
    uint64_t next_sequence;
    uint32_t next_batch;
    uint16_t inflight_count;
    uint32_t inflight_batch;
    bool fault;
};

/* Queue functions require caller serialization, including BLE callback access. */
void gw_queue_init(struct gw_queue *queue);
bool gw_queue_push(struct gw_queue *queue, uint8_t type, const uint8_t *record,
                   size_t length, uint64_t now_ms);
/* Produces/freeze a ready batch, or reserializes an existing one. link_id is caller-owned. */
bool gw_queue_batch(struct gw_queue *queue, uint64_t now_ms, struct gw_frame *frame);
/* Accepts only current batch. CUSTODY pops it, BUSY retains it, FAULT stops automatic batching. */
bool gw_queue_ack(struct gw_queue *queue, uint32_t batch, uint8_t status);

#endif
```

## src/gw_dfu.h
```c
#ifndef GW_DFU_H
#define GW_DFU_H
#include <stdbool.h>
#include <stddef.h>
#include <stdint.h>

#define GW_DFU_STATUS_SIZE 62U
#define GW_DFU_CHUNK_MAX 1024U

int gw_dfu_init(void);
bool gw_dfu_available(void);
bool gw_dfu_active(void);
void gw_dfu_poll(void);
/* Application-thread API; out has at least GW_DFU_STATUS_SIZE bytes. */
uint8_t gw_dfu_command(uint8_t opcode, const uint8_t *args, size_t length,
                       uint8_t *out, size_t *out_length);

/* RF owner rejects active connections and preserves desired configuration. */
int gw_radio_prepare_dfu(void);
void gw_radio_finish_dfu(void);
#endif
```

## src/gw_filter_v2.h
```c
#ifndef GW_FILTER_V2_H
#define GW_FILTER_V2_H
#include "gw_core.h"

#define GW_FILTER_V2_MAX 3070U
#define GW_FILTER_V2_PENDING 32U
#define GW_FILTER_V2_STATUS_SIZE 96U
struct gw_filter_v2_rule {
    uint8_t action, kind_mask;
    uint16_t field_mask;
    uint8_t name_mode, name_source, name_length;
    uint8_t name_value[29], name_mask[29];
    uint8_t ibeacon_value[16], ibeacon_mask[16];
    uint8_t rssi_mode, rssi_arg0, rssi_arg1;
    uint16_t major_value, major_mask, minor_value, minor_mask;
    uint8_t service_value[16], service_mask[16];
};
struct gw_filter_v2_config {
    struct gw_profile legacy;
    uint8_t engine, scope, rule_count;
    uint16_t pair_window_ms;
    struct gw_filter_v2_rule rules[GW_RULES_MAX];
};
enum gw_filter_v2_counter {
    GW_FILTER_SEEN, GW_FILTER_PASSED, GW_FILTER_RULE_DROPPED,
    GW_FILTER_PAIR_TIMEOUT, GW_FILTER_PAIR_AMBIGUOUS, GW_FILTER_PAIR_OVERFLOW,
    GW_FILTER_MALFORMED_AD, GW_FILTER_UNKNOWN_RSSI,
    GW_FILTER_UNSUPPORTED_CONTEXT, GW_FILTER_CONFIG_DISCARDED,
    GW_FILTER_COUNTER_COUNT
};
struct gw_filter_v2_pending { uint8_t length; uint8_t record[55]; };
struct gw_filter_v2_state {
    uint64_t counters[GW_FILTER_COUNTER_COUNT];
    struct gw_filter_v2_pending pending[GW_FILTER_V2_PENDING];
};
typedef void (*gw_filter_v2_emit)(void *user, const uint8_t *record, size_t length);
void gw_filter_v2_default(struct gw_filter_v2_config *config);
/* Parse changes output only on success; encode returns zero for invalid configs. */
bool gw_filter_v2_parse(const uint8_t *data, size_t length, struct gw_filter_v2_config *config);
size_t gw_filter_v2_encode(const struct gw_filter_v2_config *config, uint8_t *data, size_t capacity);
/* All state operations require caller serialization. Config is an immutable snapshot
 * for a feed. Clear before replacing it or changing controller identity/scan state. */
void gw_filter_v2_feed(struct gw_filter_v2_state *state, const struct gw_filter_v2_config *config,
                       const uint8_t *record, size_t length, gw_filter_v2_emit emit, void *user);
/* Advance only after all input timestamps <= watermark have been processed/published.
 * Exact deadline is inclusive; only deadline < watermark expires. */
void gw_filter_v2_advance(struct gw_filter_v2_state *state, uint64_t watermark_ms);
void gw_filter_v2_clear(struct gw_filter_v2_state *state);
void gw_filter_v2_status(const struct gw_filter_v2_state *state,
                         const struct gw_filter_v2_config *config, uint8_t out[96]);
#endif
```
